# NAVSS0_BCDMA_0_BCDMA0_CFG_GCFG register map
Vendor: Texas Instruments
Peripheral module from a debugger description file (folder J7_AHP).
Registers are 32-bit, read-only, reset 0x0 unless marked. A register's access mark holds for its fields unless they carry their own. Offsets are as the file gives them; lines under a group give offsets from that group; [hi:lo] are bit positions; {n}, {i} and the like mark numbered series; 'fields as' and 'values as' point back to an identical list; <NAME> marks a mode.

## NAVSS0_BCDMA_0_BCDMA0_CFG_GCFG
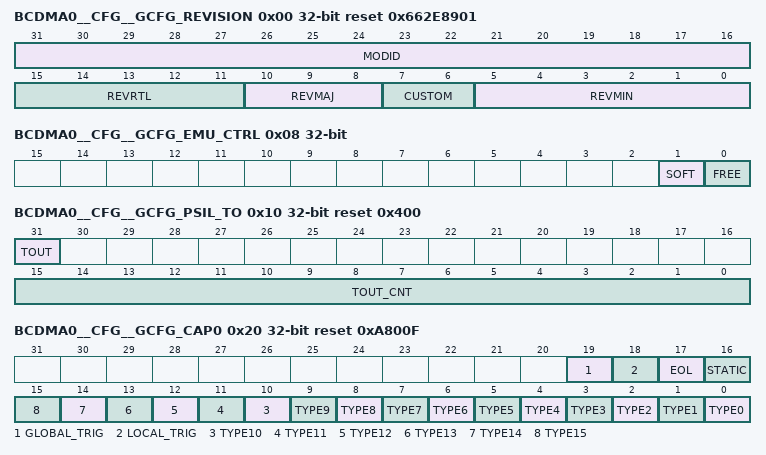
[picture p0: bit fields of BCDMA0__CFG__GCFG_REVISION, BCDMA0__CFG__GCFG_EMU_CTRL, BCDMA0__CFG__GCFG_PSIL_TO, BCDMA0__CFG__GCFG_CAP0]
0x00 BCDMA0__CFG__GCFG_REVISION reset 0x662E8901
  [31:16] MODID — Module ID field
  [15:11] REVRTL — RTL revision. Will vary depending on release.
  [10:8] REVMAJ — Major revision
  [7:6] CUSTOM
  [5:0] REVMIN — Minor revision
0x04 BCDMA0__CFG__GCFG_PERF_CTRL rw reset 0x40
  [15:0] TIMEOUT_CNT — This feature is not currently supported.
0x08 BCDMA0__CFG__GCFG_EMU_CTRL rw
  [1] SOFT, [0] FREE
0x10 BCDMA0__CFG__GCFG_PSIL_TO rw reset 0x400
  [31] TOUT — Timeout occurred. When set indicates that a timeout has occurred on a config access
  [15:0] TOUT_CNT — Timeout period. Specifies how many cycles to wait before closing up a conifiguration read or write transaction and asserting the tout bit
0x20 BCDMA0__CFG__GCFG_CAP0 reset 0xA800F
  [19] GLOBAL_TRIG — Global triggers 0 and 1 are supported
  [18] LOCAL_TRIG — Dedicated local trigger is supported
  [17] EOL — EOL field is supported
  [16] STATIC — STATIC field is supported
  [n] TYPE{n} (n=0..15) — Type {n} TR is supported
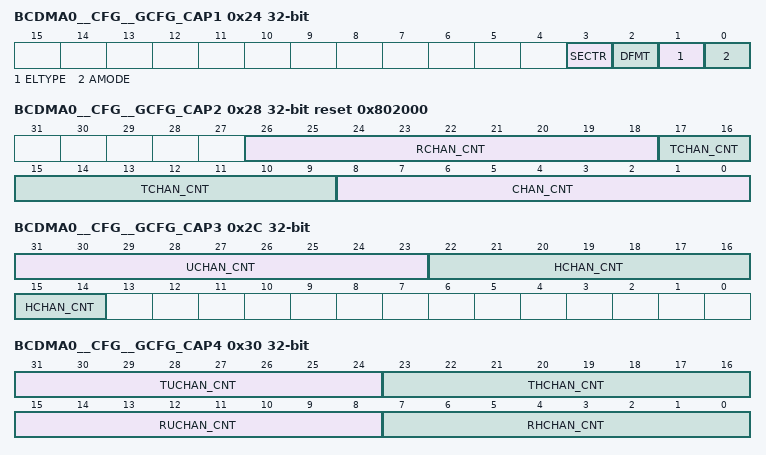
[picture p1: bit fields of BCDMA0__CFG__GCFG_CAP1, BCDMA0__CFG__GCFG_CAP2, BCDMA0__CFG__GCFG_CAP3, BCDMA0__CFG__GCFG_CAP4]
0x24 BCDMA0__CFG__GCFG_CAP1
  [3] SECTR — Maximum second TR function that is supported
  [2] DFMT — Maximum data reformatting function that is supported
  [1] ELTYPE — Maximum element type value that is supported.
  [0] AMODE — The maximum AMODE that is supported. If AMODE is supported then DIR field must be supported for that AMODE.
0x28 BCDMA0__CFG__GCFG_CAP2 reset 0x802000
  [26:18] RCHAN_CNT — Rx split channel count
  [17:9] TCHAN_CNT — Tx split channel count
  [8:0] CHAN_CNT — BC channel count
0x2C BCDMA0__CFG__GCFG_CAP3
  [31:23] UCHAN_CNT — BC ultra high capacity internal channel count
  [22:14] HCHAN_CNT — BC high capacity internal channel count
0x30 BCDMA0__CFG__GCFG_CAP4
  [31:24] TUCHAN_CNT — TX ultra high capacity internal channel count
  [23:16] THCHAN_CNT — TX high capacity internal channel count
  [15:8] RUCHAN_CNT — RX ultra high capacity internal channel count
  [7:0] RHCHAN_CNT — RX high capacity internal channel count
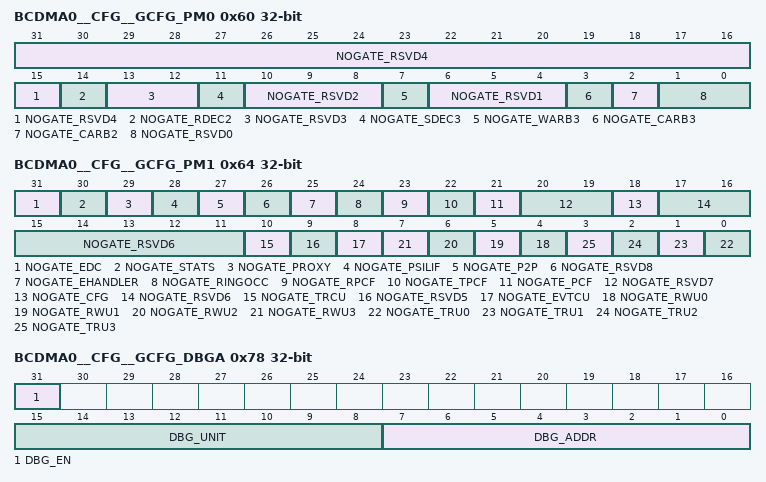
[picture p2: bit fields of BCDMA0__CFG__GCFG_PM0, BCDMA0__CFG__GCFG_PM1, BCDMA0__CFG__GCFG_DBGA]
0x60 BCDMA0__CFG__GCFG_PM0 rw
  [31:15] NOGATE_RSVD4 — Reserved PM signals.
  [14] NOGATE_RDEC2 — When set inhibits automatic gating of clock.
  [13:12] NOGATE_RSVD3 — Reserved PM signals.
  [11] NOGATE_SDEC3 — When set inhibits automatic gating of clock.
  [10:8] NOGATE_RSVD2 — Reserved PM signals.
  [7] NOGATE_WARB3 — When set inhibits automatic gating of clock.
  [6:4] NOGATE_RSVD1 — Reserved PM signals.
  [3] NOGATE_CARB3 — When set inhibits automatic gating of clock.
  [2] NOGATE_CARB2 — When set inhibits automatic gating of clock.
  [1:0] NOGATE_RSVD0 — Reserved PM signals.
0x64 BCDMA0__CFG__GCFG_PM1 rw
  [31] NOGATE_EDC — When set inhibits automatic gating of clock.
  [30] NOGATE_STATS — When set inhibits automatic gating of clock.
  [29] NOGATE_PROXY — When set inhibits automatic gating of clock.
  [28] NOGATE_PSILIF — When set inhibits automatic gating of clock.
  [27] NOGATE_P2P — When set inhibits automatic gating of clock.
  [26] NOGATE_RSVD8 — Reserved PM signals.
  [25] NOGATE_EHANDLER — When set inhibits automatic gating of clock.
  [24] NOGATE_RINGOCC — When set inhibits automatic gating of clock.
  [23] NOGATE_RPCF — When set inhibits automatic gating of clock.
  [22] NOGATE_TPCF — When set inhibits automatic gating of clock.
  [21] NOGATE_PCF — When set inhibits automatic gating of clock.
  [20:19] NOGATE_RSVD7 — Reserved PM signals.
  [18] NOGATE_CFG — When set inhibits automatic gating of clock.
  [17:11] NOGATE_RSVD6 — Reserved PM signals.
  [10] NOGATE_TRCU — When set inhibits automatic gating of clock.
  [9] NOGATE_RSVD5 — Reserved PM signals.
  [8] NOGATE_EVTCU — When set inhibits automatic gating of clock.
  [n+4] NOGATE_RWU{n} (n=0..3) — When set inhibits automatic gating of clock.
  [n] NOGATE_TRU{n} (n=0..3) — When set inhibits automatic gating of clock.
0x78 BCDMA0__CFG__GCFG_DBGA rw
  [31] DBG_EN — Debug enable
  [15:8] DBG_UNIT — Selects which unit to read debug information from
  [7:0] DBG_ADDR — Selects offset within unit to access seperate debug registers
0x7C BCDMA0__CFG__GCFG_DBGD access not given
  [31:0] DBG_DATA — Provides debug information from various internal units. The value which is read back depends on which unit and register are selected in the Debug Address Register (access R/NA)
